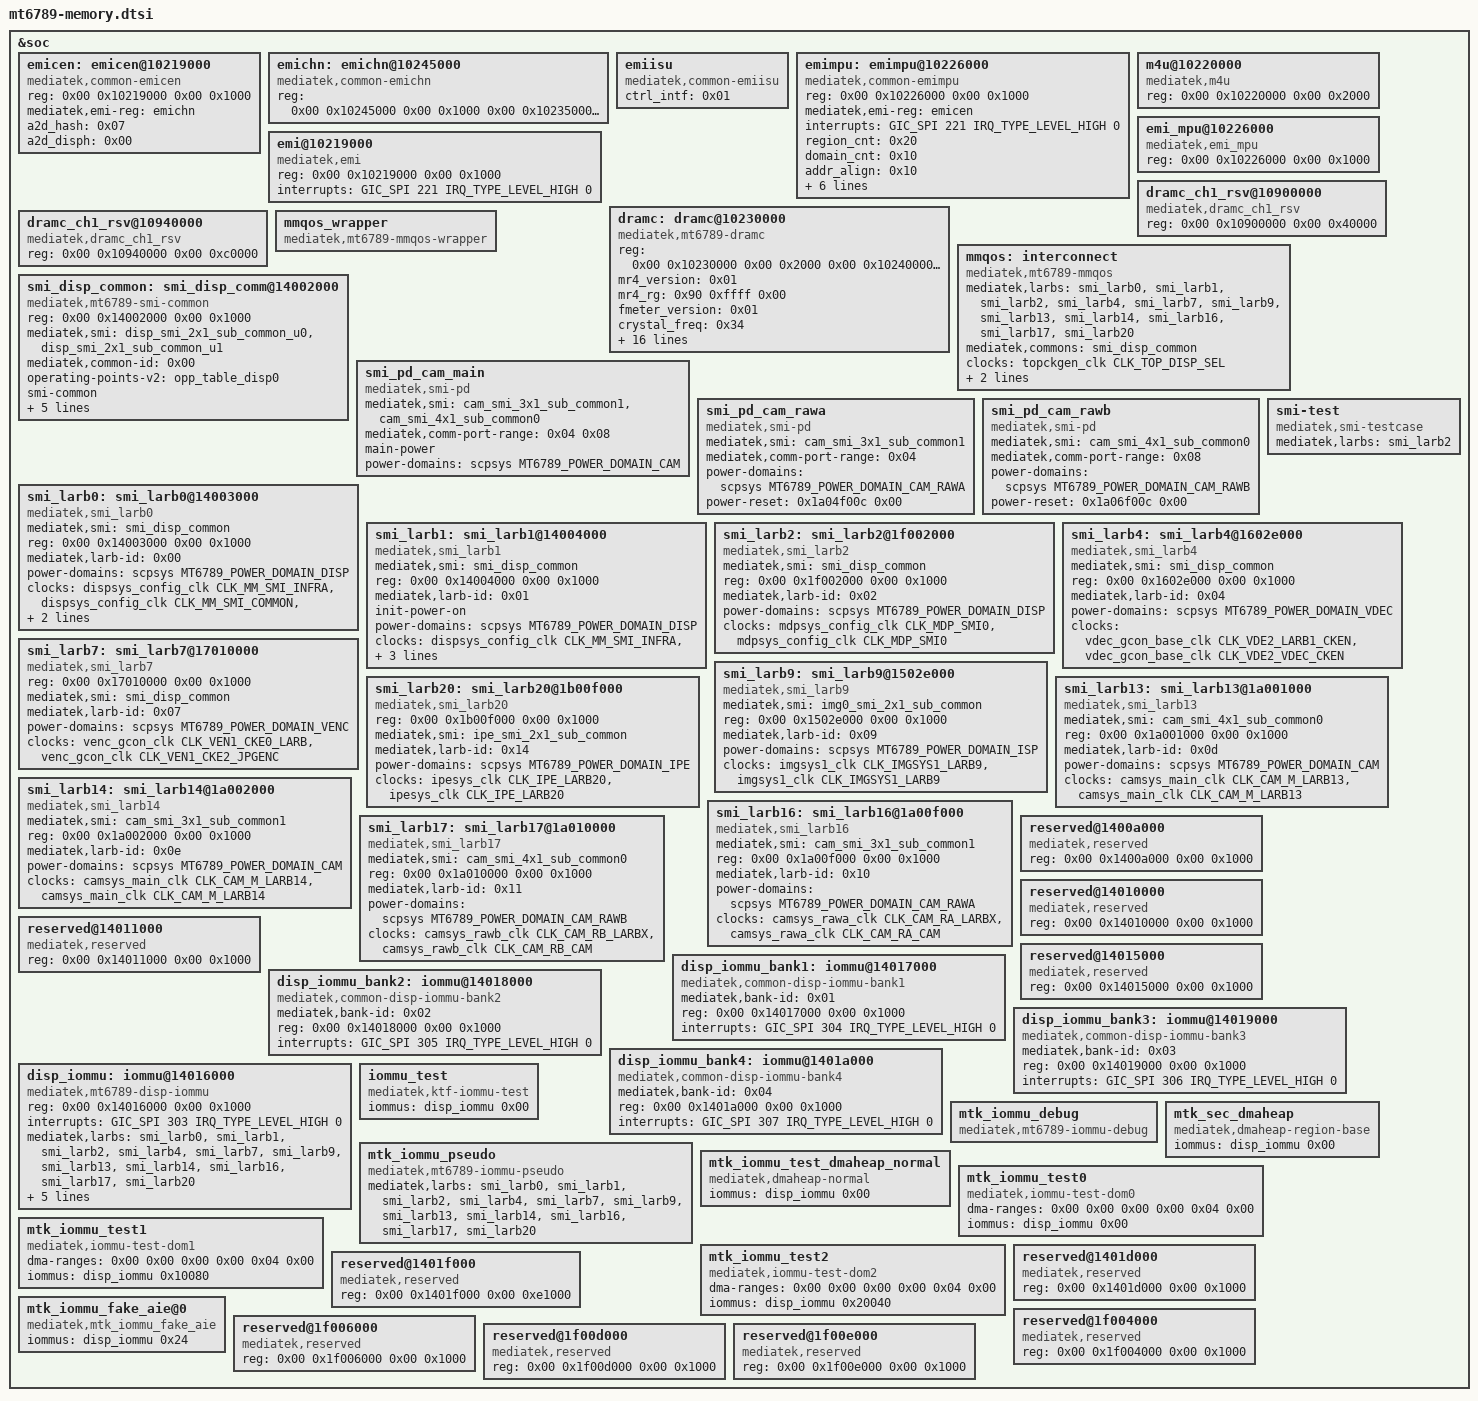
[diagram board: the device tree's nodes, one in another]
// SPDX-License-Identifier: (GPL-2.0 OR MIT)
/* MT6789 memory blocks - split out of the soc node by tools/scripts/dts-socsplit.py */

&soc {
	emicen: emicen@10219000 {
		compatible = "mediatek,common-emicen";
		reg = <0x00 0x10219000 0x00 0x1000>;
		mediatek,emi-reg = <&emichn>;
		a2d_hash = <0x07>;
		a2d_disph = <0x00>;
	};

	emichn: emichn@10245000 {
		compatible = "mediatek,common-emichn";
		reg = <0x00 0x10245000 0x00 0x1000 0x00 0x10235000 0x00 0x1000>;
	};

	emiisu {
		compatible = "mediatek,common-emiisu";
		ctrl_intf = <0x01>;
	};

	emimpu: emimpu@10226000 {
		compatible = "mediatek,common-emimpu";
		reg = <0x00 0x10226000 0x00 0x1000>;
		mediatek,emi-reg = <&emicen>;
		interrupts = <GIC_SPI 221 IRQ_TYPE_LEVEL_HIGH 0>;
		region_cnt = <0x20>;
		domain_cnt = <0x10>;
		addr_align = <0x10>;
		dump = <0x1f0 0x1f8 0x1fc>;
		clear = <0x160 0xffffffff 0x10 0x200 0x03 0x10 0x1f0 0x80000000 0x01>;
		clear_md = <0x1fc 0x80000000 0x01>;
		ctrl_intf = <0x01>;
		slverr = <0x00>;
	};

	emi@10219000 {
		compatible = "mediatek,emi";
		reg = <0x00 0x10219000 0x00 0x1000>;
		interrupts = <GIC_SPI 221 IRQ_TYPE_LEVEL_HIGH 0>;
	};

	m4u@10220000 {
		compatible = "mediatek,m4u";
		reg = <0x00 0x10220000 0x00 0x2000>;
	};

	emi_mpu@10226000 {
		compatible = "mediatek,emi_mpu";
		reg = <0x00 0x10226000 0x00 0x1000>;
	};

	dramc: dramc@10230000 {
		compatible = "mediatek,mt6789-dramc", "mediatek,common-dramc";
		reg = <0x00 0x10230000 0x00 0x2000 0x00 0x10240000 0x00 0x2000 0x00 0x10234000 0x00 0x1000 0x00 0x10244000 0x00 0x1000 0x00 0x10238000 0x00 0x2000 0x00 0x10248000 0x00 0x2000 0x00 0x10236000 0x00 0x1000 0x00 0x10246000 0x00 0x1000 0x00 0x10006000 0x00 0x1000>;
		mr4_version = <0x01>;
		mr4_rg = <0x90 0xffff 0x00>;
		fmeter_version = <0x01>;
		crystal_freq = <0x34>;
		pll_id = <0x50c 0x100 0x08>;
		shu_lv = <0x50c 0x30000 0x10>;
		shu_of = <0x700>;
		sdmpcw = <0x704 0xffff0000 0x10 0x724 0xffff0000 0x10>;
		prediv = <0x708 0xc0000 0x12 0x728 0xc0000 0x12>;
		posdiv = <0x708 0x07 0x00 0x728 0x07 0x00>;
		ckdiv4 = <0x874 0x04 0x02 0x874 0x04 0x02>;
		pll_md = <0x744 0x100 0x08 0x744 0x100 0x08>;
		cldiv2 = <0x8b4 0x02 0x01 0x8b4 0x02 0x01>;
		fbksel = <0x70c 0x40 0x06 0x70c 0x40 0x06>;
		dqsopen = <0x870 0x100000 0x14 0x870 0x100000 0x14>;
		dqopen = <0x870 0x200000 0x15 0x870 0x200000 0x15>;
		ckdiv4_ca = <0xb74 0x04 0x02 0xb74 0x04 0x02>;
	};

	dramc_ch1_rsv@10900000 {
		compatible = "mediatek,dramc_ch1_rsv";
		reg = <0x00 0x10900000 0x00 0x40000>;
	};

	dramc_ch1_rsv@10940000 {
		compatible = "mediatek,dramc_ch1_rsv";
		reg = <0x00 0x10940000 0x00 0xc0000>;
	};

	mmqos_wrapper {
		compatible = "mediatek,mt6789-mmqos-wrapper";
	};

	mmqos: interconnect {
		compatible = "mediatek,mt6789-mmqos";
		#mtk-interconnect-cells = <0x01>;
		mediatek,larbs = <&smi_larb0 &smi_larb1 &smi_larb2 &smi_larb4 &smi_larb7 &smi_larb9 &smi_larb13 &smi_larb14 &smi_larb16 &smi_larb17 &smi_larb20>;
		mediatek,commons = <&smi_disp_common>;
		clocks = <&topckgen_clk CLK_TOP_DISP_SEL>;
		clock-names = "mm";
		interconnects = <&dvfsrc 0x8 &dvfsrc 0x00 &dvfsrc 0x1a &dvfsrc 0x19>;
		interconnect-names = "icc-bw", "icc-hrt-bw";
	};

	smi_disp_common: smi_disp_comm@14002000 {
		compatible = "mediatek,mt6789-smi-common", "syscon", "mediatek,smi-common";
		reg = <0x00 0x14002000 0x00 0x1000>;
		mediatek,smi = <&disp_smi_2x1_sub_common_u0 &disp_smi_2x1_sub_common_u1>;
		mediatek,common-id = <0x00>;
		operating-points-v2 = <&opp_table_disp0>;
		smi-common;
		power-domains = <&scpsys MT6789_POWER_DOMAIN_DISP>;
		clocks = <&dispsys_config_clk CLK_MM_SMI_INFRA &dispsys_config_clk CLK_MM_SMI_COMMON &dispsys_config_clk CLK_MM_SMI_GALS &dispsys_config_clk CLK_MM_SMI_IOMMU>;
		clock-names = "apb", "smi", "gals0", "gals1";
	};

	smi_pd_cam_main: smi_pd_cam_main {
		compatible = "mediatek,smi-pd";
		mediatek,smi = <&cam_smi_3x1_sub_common1 &cam_smi_4x1_sub_common0>;
		mediatek,comm-port-range = <0x04 0x08>;
		main-power;
		power-domains = <&scpsys MT6789_POWER_DOMAIN_CAM>;
	};

	smi_pd_cam_rawa: smi_pd_cam_rawa {
		compatible = "mediatek,smi-pd";
		mediatek,smi = <&cam_smi_3x1_sub_common1>;
		mediatek,comm-port-range = <0x04>;
		power-domains = <&scpsys MT6789_POWER_DOMAIN_CAM_RAWA>;
		power-reset = <0x1a04f00c 0x00>;
	};

	smi_pd_cam_rawb: smi_pd_cam_rawb {
		compatible = "mediatek,smi-pd";
		mediatek,smi = <&cam_smi_4x1_sub_common0>;
		mediatek,comm-port-range = <0x08>;
		power-domains = <&scpsys MT6789_POWER_DOMAIN_CAM_RAWB>;
		power-reset = <0x1a06f00c 0x00>;
	};

	smi_larb0: smi_larb0@14003000 {
		compatible = "mediatek,smi_larb0", "mediatek,mt6789-smi-larb", "mediatek,smi-larb";
		mediatek,smi = <&smi_disp_common>;
		reg = <0x00 0x14003000 0x00 0x1000>;
		mediatek,larb-id = <0x00>;
		power-domains = <&scpsys MT6789_POWER_DOMAIN_DISP>;
		clocks = <&dispsys_config_clk CLK_MM_SMI_INFRA &dispsys_config_clk CLK_MM_SMI_COMMON &dispsys_config_clk CLK_MM_SMI_GALS &dispsys_config_clk CLK_MM_SMI_IOMMU>;
		clock-names = "apb", "smi", "gals0", "gals1";
	};

	smi_larb1: smi_larb1@14004000 {
		compatible = "mediatek,smi_larb1", "mediatek,mt6789-smi-larb", "mediatek,smi-larb";
		mediatek,smi = <&smi_disp_common>;
		reg = <0x00 0x14004000 0x00 0x1000>;
		mediatek,larb-id = <0x01>;
		init-power-on;
		power-domains = <&scpsys MT6789_POWER_DOMAIN_DISP>;
		clocks = <&dispsys_config_clk CLK_MM_SMI_INFRA &dispsys_config_clk CLK_MM_SMI_COMMON &dispsys_config_clk CLK_MM_SMI_GALS &dispsys_config_clk CLK_MM_SMI_IOMMU>;
		clock-names = "apb", "smi", "gals0", "gals1";
	};

	smi-test {
		compatible = "mediatek,smi-testcase";
		mediatek,larbs = <&smi_larb2>;
	};

	smi_larb2: smi_larb2@1f002000 {
		compatible = "mediatek,smi_larb2", "mediatek,mt6789-smi-larb", "mediatek,smi-larb";
		mediatek,smi = <&smi_disp_common>;
		reg = <0x00 0x1f002000 0x00 0x1000>;
		mediatek,larb-id = <0x02>;
		power-domains = <&scpsys MT6789_POWER_DOMAIN_DISP>;
		clocks = <&mdpsys_config_clk CLK_MDP_SMI0 &mdpsys_config_clk CLK_MDP_SMI0>;
		clock-names = "apb", "smi";
	};

	smi_larb4: smi_larb4@1602e000 {
		compatible = "mediatek,smi_larb4", "mediatek,mt6789-smi-larb", "mediatek,smi-larb";
		mediatek,smi = <&smi_disp_common>;
		reg = <0x00 0x1602e000 0x00 0x1000>;
		mediatek,larb-id = <0x04>;
		power-domains = <&scpsys MT6789_POWER_DOMAIN_VDEC>;
		clocks = <&vdec_gcon_base_clk CLK_VDE2_LARB1_CKEN &vdec_gcon_base_clk CLK_VDE2_VDEC_CKEN>;
		clock-names = "apb", "smi";
	};

	smi_larb7: smi_larb7@17010000 {
		compatible = "mediatek,smi_larb7", "mediatek,mt6789-smi-larb", "mediatek,smi-larb";
		reg = <0x00 0x17010000 0x00 0x1000>;
		mediatek,smi = <&smi_disp_common>;
		mediatek,larb-id = <0x07>;
		power-domains = <&scpsys MT6789_POWER_DOMAIN_VENC>;
		clocks = <&venc_gcon_clk CLK_VEN1_CKE0_LARB &venc_gcon_clk CLK_VEN1_CKE2_JPGENC>;
		clock-names = "apb", "smi";
	};

	smi_larb9: smi_larb9@1502e000 {
		compatible = "mediatek,smi_larb9", "mediatek,mt6789-smi-larb", "mediatek,smi-larb";
		mediatek,smi = <&img0_smi_2x1_sub_common>;
		reg = <0x00 0x1502e000 0x00 0x1000>;
		mediatek,larb-id = <0x09>;
		power-domains = <&scpsys MT6789_POWER_DOMAIN_ISP>;
		clocks = <&imgsys1_clk CLK_IMGSYS1_LARB9 &imgsys1_clk CLK_IMGSYS1_LARB9>;
		clock-names = "apb", "smi";
	};

	smi_larb20: smi_larb20@1b00f000 {
		compatible = "mediatek,smi_larb20", "mediatek,mt6789-smi-larb", "mediatek,smi-larb";
		reg = <0x00 0x1b00f000 0x00 0x1000>;
		mediatek,smi = <&ipe_smi_2x1_sub_common>;
		mediatek,larb-id = <0x14>;
		power-domains = <&scpsys MT6789_POWER_DOMAIN_IPE>;
		clocks = <&ipesys_clk CLK_IPE_LARB20 &ipesys_clk CLK_IPE_LARB20>;
		clock-names = "apb", "smi";
	};

	smi_larb13: smi_larb13@1a001000 {
		compatible = "mediatek,smi_larb13", "mediatek,mt6789-smi-larb", "mediatek,smi-larb";
		mediatek,smi = <&cam_smi_4x1_sub_common0>;
		reg = <0x00 0x1a001000 0x00 0x1000>;
		mediatek,larb-id = <0x0d>;
		power-domains = <&scpsys MT6789_POWER_DOMAIN_CAM>;
		clocks = <&camsys_main_clk CLK_CAM_M_LARB13 &camsys_main_clk CLK_CAM_M_LARB13>;
		clock-names = "apb", "smi";
	};

	smi_larb14: smi_larb14@1a002000 {
		compatible = "mediatek,smi_larb14", "mediatek,mt6789-smi-larb", "mediatek,smi-larb";
		mediatek,smi = <&cam_smi_3x1_sub_common1>;
		reg = <0x00 0x1a002000 0x00 0x1000>;
		mediatek,larb-id = <0x0e>;
		power-domains = <&scpsys MT6789_POWER_DOMAIN_CAM>;
		clocks = <&camsys_main_clk CLK_CAM_M_LARB14 &camsys_main_clk CLK_CAM_M_LARB14>;
		clock-names = "apb", "smi";
	};

	smi_larb16: smi_larb16@1a00f000 {
		compatible = "mediatek,smi_larb16", "mediatek,mt6789-smi-larb", "mediatek,smi-larb";
		mediatek,smi = <&cam_smi_3x1_sub_common1>;
		reg = <0x00 0x1a00f000 0x00 0x1000>;
		mediatek,larb-id = <0x10>;
		power-domains = <&scpsys MT6789_POWER_DOMAIN_CAM_RAWA>;
		clocks = <&camsys_rawa_clk CLK_CAM_RA_LARBX &camsys_rawa_clk CLK_CAM_RA_CAM>;
		clock-names = "apb", "smi";
	};

	smi_larb17: smi_larb17@1a010000 {
		compatible = "mediatek,smi_larb17", "mediatek,mt6789-smi-larb", "mediatek,smi-larb";
		mediatek,smi = <&cam_smi_4x1_sub_common0>;
		reg = <0x00 0x1a010000 0x00 0x1000>;
		mediatek,larb-id = <0x11>;
		power-domains = <&scpsys MT6789_POWER_DOMAIN_CAM_RAWB>;
		clocks = <&camsys_rawb_clk CLK_CAM_RB_LARBX &camsys_rawb_clk CLK_CAM_RB_CAM>;
		clock-names = "apb", "smi";
	};

	reserved@1400a000 {
		compatible = "mediatek,reserved";
		reg = <0x00 0x1400a000 0x00 0x1000>;
	};

	reserved@14010000 {
		compatible = "mediatek,reserved";
		reg = <0x00 0x14010000 0x00 0x1000>;
	};

	reserved@14011000 {
		compatible = "mediatek,reserved";
		reg = <0x00 0x14011000 0x00 0x1000>;
	};

	reserved@14015000 {
		compatible = "mediatek,reserved";
		reg = <0x00 0x14015000 0x00 0x1000>;
	};

	disp_iommu_bank1: iommu@14017000 {
		compatible = "mediatek,common-disp-iommu-bank1";
		mediatek,bank-id = <0x01>;
		reg = <0x00 0x14017000 0x00 0x1000>;
		interrupts = <GIC_SPI 304 IRQ_TYPE_LEVEL_HIGH 0>;
	};

	disp_iommu_bank2: iommu@14018000 {
		compatible = "mediatek,common-disp-iommu-bank2";
		mediatek,bank-id = <0x02>;
		reg = <0x00 0x14018000 0x00 0x1000>;
		interrupts = <GIC_SPI 305 IRQ_TYPE_LEVEL_HIGH 0>;
	};

	disp_iommu_bank3: iommu@14019000 {
		compatible = "mediatek,common-disp-iommu-bank3";
		mediatek,bank-id = <0x03>;
		reg = <0x00 0x14019000 0x00 0x1000>;
		interrupts = <GIC_SPI 306 IRQ_TYPE_LEVEL_HIGH 0>;
	};

	disp_iommu_bank4: iommu@1401a000 {
		compatible = "mediatek,common-disp-iommu-bank4";
		mediatek,bank-id = <0x04>;
		reg = <0x00 0x1401a000 0x00 0x1000>;
		interrupts = <GIC_SPI 307 IRQ_TYPE_LEVEL_HIGH 0>;
	};

	disp_iommu: iommu@14016000 {
		compatible = "mediatek,mt6789-disp-iommu";
		reg = <0x00 0x14016000 0x00 0x1000>;
		interrupts = <GIC_SPI 303 IRQ_TYPE_LEVEL_HIGH 0>;
		mediatek,larbs = <&smi_larb0 &smi_larb1 &smi_larb2 &smi_larb4 &smi_larb7 &smi_larb9 &smi_larb13 &smi_larb14 &smi_larb16 &smi_larb17 &smi_larb20>;
		mediatek,iommu_banks = <&disp_iommu_bank1 &disp_iommu_bank2 &disp_iommu_bank3 &disp_iommu_bank4>;
		power-domains = <&scpsys MT6789_POWER_DOMAIN_DISP>;
		clocks = <&dispsys_config_clk CLK_MM_SMI_IOMMU>;
		clock-names = "bclk";
		#iommu-cells = <0x01>;
	};

	iommu_test {
		compatible = "mediatek,ktf-iommu-test";
		iommus = <&disp_iommu 0x00>;
	};

	mtk_iommu_debug {
		compatible = "mediatek,mt6789-iommu-debug";
	};

	mtk_iommu_pseudo {
		compatible = "mediatek,mt6789-iommu-pseudo";
		mediatek,larbs = <&smi_larb0 &smi_larb1 &smi_larb2 &smi_larb4 &smi_larb7 &smi_larb9 &smi_larb13 &smi_larb14 &smi_larb16 &smi_larb17 &smi_larb20>;
	};

	mtk_sec_dmaheap {
		compatible = "mediatek,dmaheap-region-base";
		iommus = <&disp_iommu 0x00>;
	};

	mtk_iommu_test_dmaheap_normal {
		compatible = "mediatek,dmaheap-normal";
		iommus = <&disp_iommu 0x00>;
	};

	mtk_iommu_test0 {
		#address-cells = <2>;
		#size-cells = <2>;
		compatible = "mediatek,iommu-test-dom0";
		dma-ranges = <0x00 0x00 0x00 0x00 0x04 0x00>;
		iommus = <&disp_iommu 0x00>;
	};

	mtk_iommu_test1 {
		#address-cells = <2>;
		#size-cells = <2>;
		compatible = "mediatek,iommu-test-dom1";
		dma-ranges = <0x00 0x00 0x00 0x00 0x04 0x00>;
		iommus = <&disp_iommu 0x10080>;
	};

	mtk_iommu_test2 {
		#address-cells = <2>;
		#size-cells = <2>;
		compatible = "mediatek,iommu-test-dom2";
		dma-ranges = <0x00 0x00 0x00 0x00 0x04 0x00>;
		iommus = <&disp_iommu 0x20040>;
	};

	reserved@1401d000 {
		compatible = "mediatek,reserved";
		reg = <0x00 0x1401d000 0x00 0x1000>;
	};

	reserved@1401f000 {
		compatible = "mediatek,reserved";
		reg = <0x00 0x1401f000 0x00 0xe1000>;
	};

	mtk_iommu_fake_aie@0 {
		compatible = "mediatek,mtk_iommu_fake_aie";
		iommus = <&disp_iommu 0x24>;
	};

	reserved@1f004000 {
		compatible = "mediatek,reserved";
		reg = <0x00 0x1f004000 0x00 0x1000>;
	};

	reserved@1f006000 {
		compatible = "mediatek,reserved";
		reg = <0x00 0x1f006000 0x00 0x1000>;
	};

	reserved@1f00d000 {
		compatible = "mediatek,reserved";
		reg = <0x00 0x1f00d000 0x00 0x1000>;
	};

	reserved@1f00e000 {
		compatible = "mediatek,reserved";
		reg = <0x00 0x1f00e000 0x00 0x1000>;
	};

};
